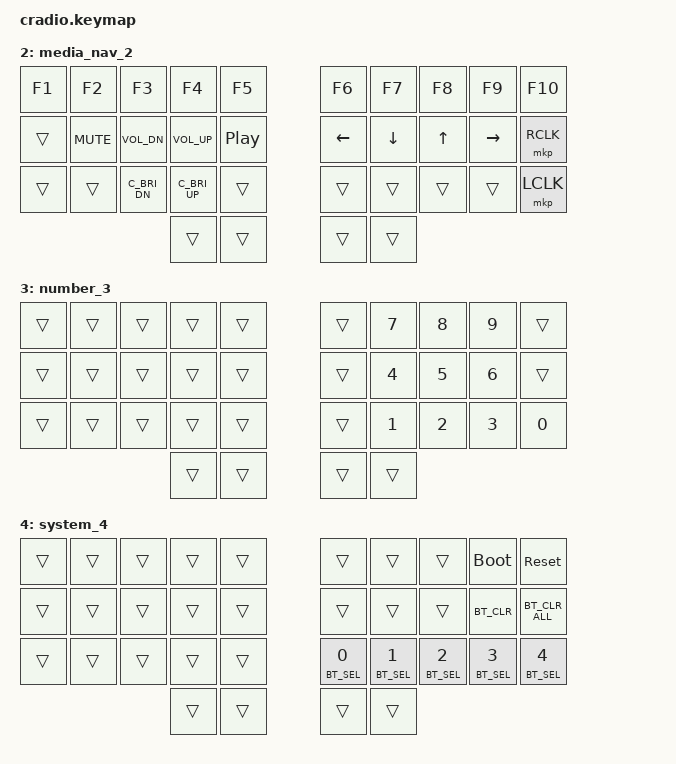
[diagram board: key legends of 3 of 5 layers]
// Copyright (c) 2022 The ZMK Contributors
// SPDX-License-Identifier: MIT

#include <behaviors.dtsi>
#include <dt-bindings/zmk/keys.h>
#include <dt-bindings/zmk/bt.h>

// Home row mods macro
#define HRML(k1,k2,k3,k4,k5) &ht LGUI k1  &ht LCTRL k2  &ht LALT k3  &ht LSHIFT k4  &ht LA(LC(LG(LSHIFT))) k5
#define HRMR(k1,k2,k3,k4,k5) &ht LA(LC(LG(LSHIFT))) k1  &ht LSHIFT k2  &ht LALT k3  &ht LCTRL k4  &ht LGUI k5

/ {
    behaviors {
        ht: hold_tap {
            compatible = "zmk,behavior-hold-tap";
            #binding-cells = <2>;
            flavor = "tap-preferred";
            tapping-term-ms = <220>;
            quick-tap-ms = <150>;
            require-prior-idle-ms = <100>;
            bindings = <&kp>, <&kp>;
        };
    };

    conditional_layers {
        compatible = "zmk,conditional-layers";
        tri_layer {
            if-layers = <1 2>;
            then-layer = <3>;
        };
    };

    keymap {
        compatible = "zmk,keymap";
        main_0 {
            bindings = <
        //╭──────────┬──────────┬──────────┬──────────┬──────────╮   ╭──────────┬──────────┬──────────┬──────────┬──────────╮
        //│  Q       │  W       │  E       │  R       │  T       │   │  Y       │  U       │  I       │  O       │  P       │
            &kp Q      &kp W      &kp E      &kp R      &kp T          &kp Y      &kp U      &kp I      &kp O      &kp P
        //├──────────┼──────────┼──────────┼──────────┼──────────┤   ├──────────┼──────────┼──────────┼──────────┼──────────┤
        //│  A       │  S       │  D       │  F       │  G       │   │  H       │  J       │  K       │  L       │   ;      │
            HRML(A,        S,         D,         F,         G)          HRMR(H,       J,         K,          L,    SEMICOLON)
        //├──────────┼──────────┼──────────┼──────────┼──────────┤   ├──────────┼──────────┼──────────┼──────────┼──────────┤
        //│  Z       │  X       │  C       │  V       │  B       │   │  N       │  M       │ , <      │ . >      │ / ?      │
            &kp Z      &kp X      &kp C      &kp V      &kp B          &kp N      &kp M      &kp COMMA  &kp DOT    &kp FSLH
        //╰──────────┴──────────┴──────────┼──────────┼──────────┤   ├──────────┼──────────┼──────────┴──────────┴──────────╯
                                            &lt 1 TAB  &lt 4 ENTER    &lt 3 SPACE  &lt 2 BSPC
        //                                 ╰──────────┴──────────╯   ╰──────────┴──────────╯
            >;
        };

        sym_1 {
            bindings = <
        //╭──────────┬──────────┬──────────┬──────────┬──────────╮   ╭──────────┬──────────┬──────────┬──────────┬──────────╮
        //│          │          │          │          │          │   │  &       │  [       │  ]       │  ^       │  %       │
            &trans     &trans     &trans     &trans     &trans         &kp AMPS   &kp LBKT  &kp RBKT   &kp CARET   &kp PRCNT
        //├──────────┼──────────┼──────────┼──────────┼──────────┤   ├──────────┼──────────┼──────────┼──────────┼──────────┤
        //│  !       │  @       │  #       │  $       │  =       │   │ -        │  (       │  )       │  *       │  '       │
            HRML(EXCL,     AT,       HASH,      DLLR,      EQUAL)     HRMR(MINUS,    LPAR,      RPAR,      ASTRK, SINGLE_QUOTE)  
        //├──────────┼──────────┼──────────┼──────────┼──────────┤   ├──────────┼──────────┼──────────┼──────────┼──────────┤
        //│          │  CAPS    │  RALT    │  ESC     │          │   │ _        │  {       │  }       │  `       │  \       │
           &trans      &kp CLCK   &kp RALT   &kp ESCAPE  &trans       &kp UNDER   &kp LBRC   &kp RBRC   &kp GRAVE   &kp BSLH
        //╰──────────┴──────────┴──────────┼──────────┼──────────┤   ├──────────┼──────────┼──────────┴──────────┴──────────╯
                                             &trans     &trans         &trans     &trans
        //                                 ╰──────────┴──────────╯   ╰──────────┴──────────╯
            >;
        };

        media_nav_2 {
            bindings = <
        //╭──────────┬──────────┬──────────┬──────────┬──────────╮   ╭──────────┬──────────┬──────────┬──────────┬──────────╮
        //│  F1      │  F2      │  F3      │  F4      │  F5      │   │  F6      │  F7      │  F8      │  F9      │  F10     │
            &kp F1     &kp F2     &kp F3     &kp F4     &kp F5         &kp F6     &kp F7     &kp F8     &kp F9     &kp F10
        //├──────────┼──────────┼──────────┼──────────┼──────────┤   ├──────────┼──────────┼──────────┼──────────┼──────────┤
        //│          │ MUTE     │ VOL d    │ VOL u    │ PLY/PSE  │   │  LEFT    │  DOWN    │  UP      │  RIGHT   │ R Click  │
           &trans   &kp C_MUTE  &kp C_VOL_DN  &kp C_VOL_UP  &kp C_PP   &kp LEFT   &kp DOWN   &kp UP    &kp RIGHT  &mkp RCLK
        //├──────────┼──────────┼──────────┼──────────┼──────────┤   ├──────────┼──────────┼──────────┼──────────┼──────────┤
        //│          │          │ BRGHT d  │ BRGHT u  │          │   │          │          │          │          │ L Click  │
            &trans    &trans     &C_BRI_DN   &C_BRI_UP  &trans         &trans     &trans     &trans     &trans     &mkp LCLK
        //╰──────────┴──────────┴──────────┼──────────┼──────────┤   ├──────────┼──────────┼──────────┴──────────┴──────────╯
                                             &trans     &trans         &trans     &trans
        //                                 ╰──────────┴──────────╯   ╰──────────┴──────────╯
            >;
        };

        number_3 {
            bindings = <
        //╭──────────┬──────────┬──────────┬──────────┬──────────╮   ╭──────────┬──────────┬──────────┬──────────┬──────────╮
        //│          │          │          │          │          │   │          │  7       │  8       │  9       │          │
            &trans     &trans     &trans     &trans     &trans         &trans     &kp N7     &kp N8     &kp N9     &trans
        //├──────────┼──────────┼──────────┼──────────┼──────────┤   ├──────────┼──────────┼──────────┼──────────┼──────────┤
        //│          │          │          │          │          │   │          │  4       │  5       │  6       │          │
            &trans     &trans     &trans     &trans     &trans         &trans     &kp N4     &kp N5     &kp N6     &trans   
        //├──────────┼──────────┼──────────┼──────────┼──────────┤   ├──────────┼──────────┼──────────┼──────────┼──────────┤
        //│          │          │          │          │          │   │          │  1       │  2       │  3       │  0       │
            &trans     &trans     &trans     &trans     &trans         &trans     &kp N1     &kp N2     &kp N3     &kp N0
        //╰──────────┴──────────┴──────────┼──────────┼──────────┤   ├──────────┼──────────┼──────────┴──────────┴──────────╯
                                             &trans     &trans         &trans     &trans
        //                                 ╰──────────┴──────────╯   ╰──────────┴──────────╯
            >;
        };

        system_4 {
            bindings = <
        //╭──────────┬──────────┬──────────┬──────────┬──────────╮   ╭──────────┬──────────┬──────────┬──────────┬──────────╮
        //│          │          │          │          │          │   │          │          │          │          │          │
            &trans     &trans     &trans     &trans     &trans         &trans     &trans     &trans    &bootloader  &sys_reset
        //├──────────┼──────────┼──────────┼──────────┼──────────┤   ├──────────┼──────────┼──────────┼──────────┼──────────┤
        //│          │          │          │          │          │   │          │          │          │  BT Clr  │BT Clr all│
            &trans     &trans     &trans     &trans     &trans         &trans     &trans     &trans     &BT_CLR   &BT_CLR_ALL   
        //├──────────┼──────────┼──────────┼──────────┼──────────┤   ├──────────┼──────────┼──────────┼──────────┼──────────┤
        //│          │          │          │          │          │   │  BT 0    │  BT 1    │  BT 2    │  BT 3    │  BT 4    │
            &trans     &trans     &trans     &trans     &trans         &BT_SEL 0  &BT_SEL 1  &BT_SEL 2  &BT_SEL 3  &BT_SEL 4
        //╰──────────┴──────────┴──────────┼──────────┼──────────┤   ├──────────┼──────────┼──────────┴──────────┴──────────╯
                                             &trans     &trans         &trans     &trans
        //                                 ╰──────────┴──────────╯   ╰──────────┴──────────╯
            >;
        };
    };
};
